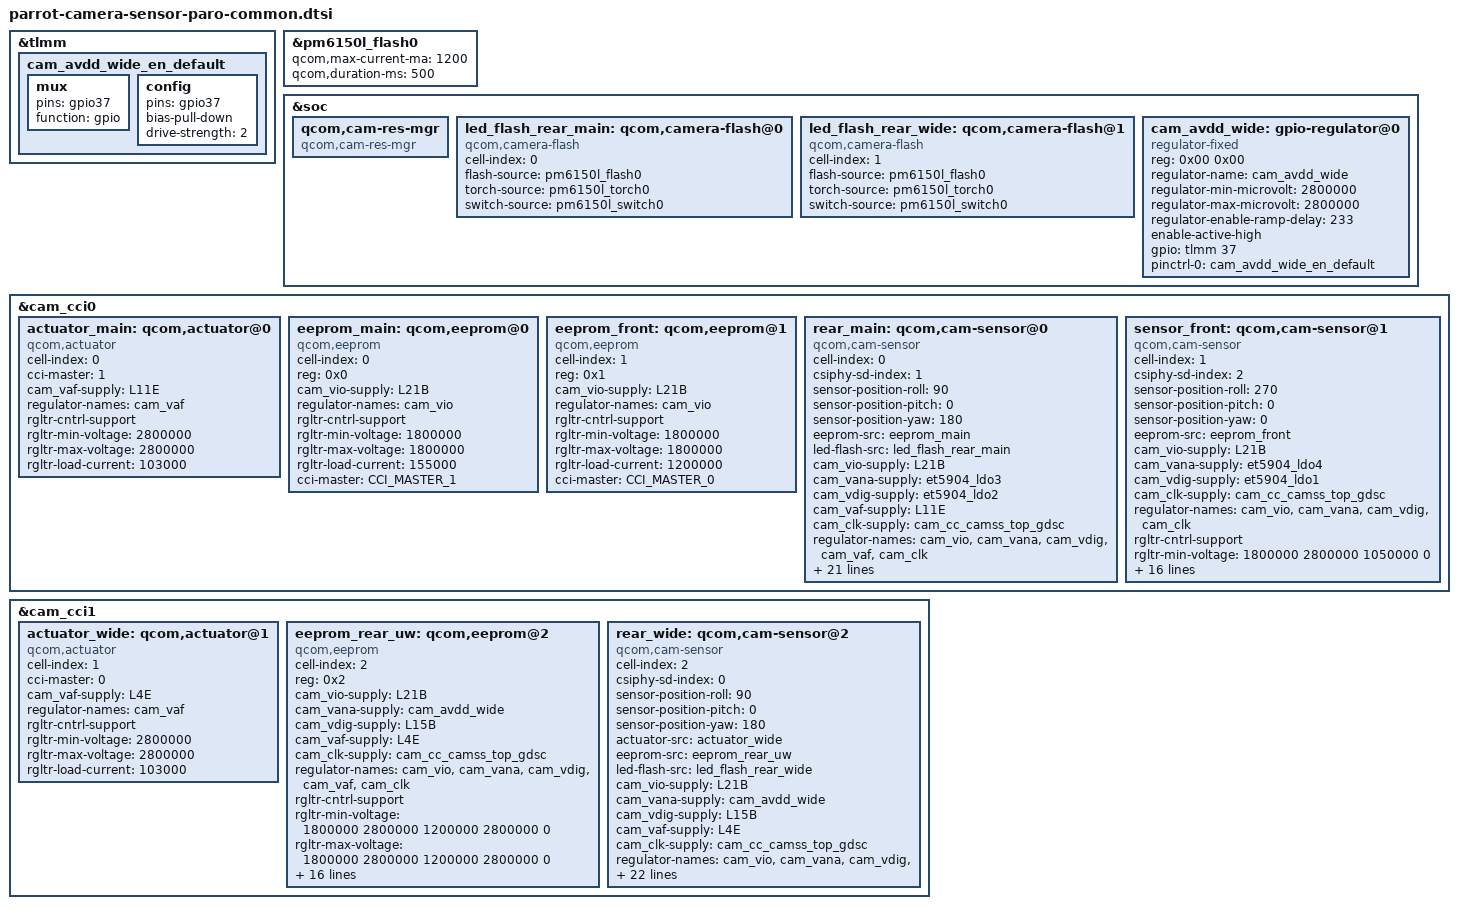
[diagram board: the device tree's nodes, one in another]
/*
   This base is original from "cape-camera-sensor-bronco-common.dtsi"
*/
#include <dt-bindings/clock/qcom,camcc-parrot.h>
#include <dt-bindings/msm-camera.h>

&tlmm {
	cam_avdd_wide_en_default: cam_avdd_wide_en_default {
		mux {
			pins = "gpio37";
			function = "gpio";
		};

		config {
			pins = "gpio37";
			bias-pull-down; /* PULL DOWN */
			drive-strength = <2>; /* 2 MA */
		};
	};

};

&pm6150l_flash0{
	qcom,max-current-ma = <1200>;
	qcom,duration-ms = <500>;
};

&soc {
	qcom,cam-res-mgr {
		compatible = "qcom,cam-res-mgr";
		status = "ok";
	};

	led_flash_rear_main: qcom,camera-flash@0 {
		cell-index = <0>;
		compatible = "qcom,camera-flash";
		flash-source = <&pm6150l_flash0>;
		torch-source = <&pm6150l_torch0>;
		switch-source = <&pm6150l_switch0>;
		status = "ok";
	};

	led_flash_rear_wide: qcom,camera-flash@1 {
		cell-index = <1>;
		compatible = "qcom,camera-flash";
		flash-source = <&pm6150l_flash0>;
		torch-source = <&pm6150l_torch0>;
		switch-source = <&pm6150l_switch0>;
		status = "ok";
	};

	cam_avdd_wide: gpio-regulator@0 {
		compatible = "regulator-fixed";
		reg = <0x00 0x00>;
		regulator-name = "cam_avdd_wide";
		regulator-min-microvolt = <2800000>;
		regulator-max-microvolt = <2800000>;
		regulator-enable-ramp-delay = <233>;
		enable-active-high;
		gpio = <&tlmm 37 0>;
		pinctrl-names = "default";
		pinctrl-0 = <&cam_avdd_wide_en_default>;
	};

};

&cam_cci0 {
	actuator_main: qcom,actuator@0 {
		cell-index = <0>;
		compatible = "qcom,actuator";
		cci-master = <1>;
		cam_vaf-supply = <&L11E>;
		regulator-names = "cam_vaf";
		rgltr-cntrl-support;
		rgltr-min-voltage = <2800000>;
		rgltr-max-voltage = <2800000>;
		rgltr-load-current = <103000>;
		status = "ok";
	};

	eeprom_main: qcom,eeprom@0 {
		cell-index = <0>;
		reg = <0x0>;
		compatible = "qcom,eeprom";
		cam_vio-supply  = <&L21B>;
		regulator-names = "cam_vio";
		rgltr-cntrl-support;
		rgltr-min-voltage  = <1800000>;
		rgltr-max-voltage  = <1800000>;
		rgltr-load-current = <155000>;
		cci-master = <CCI_MASTER_1>;
		status = "ok";
	};

	eeprom_front: qcom,eeprom@1 {
		cell-index = <1>;
		reg = <0x1>;
		compatible = "qcom,eeprom";
		cam_vio-supply  = <&L21B>;
		regulator-names = "cam_vio";
		rgltr-cntrl-support;
		rgltr-min-voltage  = <1800000>;
		rgltr-max-voltage  = <1800000>;
		rgltr-load-current = <1200000>;
		cci-master = <CCI_MASTER_0>;
		status = "ok";
	};

	rear_main: qcom,cam-sensor@0 {
		cell-index = <0>;
		compatible = "qcom,cam-sensor";
		csiphy-sd-index = <1>;
		sensor-position-roll = <90>;
		sensor-position-pitch = <0>;
		sensor-position-yaw = <180>;
		// actuator-src  = <&actuator_main>;
		eeprom-src    = <&eeprom_main>;
		led-flash-src = <&led_flash_rear_main>;
		cam_vio-supply  = <&L21B>;
		cam_vana-supply = <&et5904_ldo3>;
		cam_vdig-supply = <&et5904_ldo2>;
		cam_vaf-supply = <&L11E>;
		cam_clk-supply  = <&cam_cc_camss_top_gdsc>;
		regulator-names = "cam_vio", "cam_vana", "cam_vdig", "cam_vaf", "cam_clk" ;
		rgltr-cntrl-support;
		rgltr-min-voltage  = <1800000 2800000 1100000 2800000 0>;
		rgltr-max-voltage  = <1800000 2800000 1104000 2800000 0>;
		rgltr-load-current = <155000 155000 680000 103000 0>;
		gpio-no-mux = <0>;
		pinctrl-names = "cam_default", "cam_suspend";
		pinctrl-0 = <&cam_sensor_mclk1_active	&cam_sensor_active_rst1>;
		pinctrl-1 = <&cam_sensor_mclk1_suspend	&cam_sensor_suspend_rst1>;
		gpios = <&tlmm 40 0>, <&tlmm 45 0>;
		gpio-reset = <1>;
		gpio-req-tbl-num   = <0 1>;
		gpio-req-tbl-flags = <1 0>;
		gpio-req-tbl-label = "CAMIF_MCLK1", "CAM_RESET1";
		cci-master = <CCI_MASTER_1>;
		clocks = <&camcc CAM_CC_MCLK1_CLK>;
		clock-names = "cam_clk";
		clock-cntl-level = "nominal";
		clock-rates = <24000000>;
		status = "ok";
	};

	sensor_front: qcom,cam-sensor@1 {
		cell-index = <1>;
		compatible = "qcom,cam-sensor";
		csiphy-sd-index = <2>;
		sensor-position-roll = <270>;
		sensor-position-pitch = <0>;
		sensor-position-yaw = <0>;
		eeprom-src   = <&eeprom_front>;
		cam_vio-supply  = <&L21B>;
		cam_vana-supply = <&et5904_ldo4>;
		cam_vdig-supply = <&et5904_ldo1>;
		cam_clk-supply  = <&cam_cc_camss_top_gdsc>;
		regulator-names = "cam_vio", "cam_vana", "cam_vdig", "cam_clk";
		rgltr-cntrl-support;
		rgltr-min-voltage  = <1800000 2800000 1050000 0>;
		rgltr-max-voltage  = <1800000 2800000 1050000 0>;
		rgltr-load-current = <1200000 1200000 680000 0>;
		gpio-no-mux = <0>;
		pinctrl-names = "cam_default", "cam_suspend";
		pinctrl-0 = <&cam_sensor_mclk0_active	&cam_sensor_active_rst0>;
		pinctrl-1 = <&cam_sensor_mclk0_suspend	&cam_sensor_suspend_rst0>;
		gpios = <&tlmm 39 0>, <&tlmm 44 0>;
		gpio-reset = <1>;
		gpio-req-tbl-num = <0 1>;
		gpio-req-tbl-flags = <1 0>;
		gpio-req-tbl-label = "CAMIF_MCLK0", "CAM_RESET0";
		cci-master = <CCI_MASTER_0>;
		clocks = <&camcc CAM_CC_MCLK0_CLK>;
		clock-names = "cam_clk";
		clock-cntl-level = "nominal";
		clock-rates = <24000000>;
		status = "ok";
	};
};

&cam_cci1 {
	actuator_wide: qcom,actuator@1 {
		cell-index = <1>;
		compatible = "qcom,actuator";
		cci-master = <0>;
		cam_vaf-supply = <&L4E>;
		regulator-names = "cam_vaf";
		rgltr-cntrl-support;
		rgltr-min-voltage = <2800000>;
		rgltr-max-voltage = <2800000>;
		rgltr-load-current = <103000>;
		status = "ok";
	};

	eeprom_rear_uw: qcom,eeprom@2 {
		cell-index = <2>;
		reg = <0x2>;
		compatible = "qcom,eeprom";
		cam_vio-supply  = <&L21B>;
		cam_vana-supply = <&cam_avdd_wide>;
		cam_vdig-supply = <&L15B>;
		cam_vaf-supply = <&L4E>;
		cam_clk-supply  = <&cam_cc_camss_top_gdsc>;
		regulator-names = "cam_vio", "cam_vana", "cam_vdig", "cam_vaf", "cam_clk";
		rgltr-cntrl-support;
		rgltr-min-voltage  = <1800000 2800000 1200000 2800000 0>;
		rgltr-max-voltage  = <1800000 2800000 1200000 2800000 0>;
		rgltr-load-current = <1200000 1200000 680000 103000 0>;
		gpio-no-mux = <0>;
		pinctrl-names = "cam_default", "cam_suspend";
		pinctrl-0 = <&cam_sensor_mclk2_active	&cam_sensor_active_rst2>;
		pinctrl-1 = <&cam_sensor_mclk2_suspend	&cam_sensor_suspend_rst2>;
		gpios = <&tlmm 41 0>, <&tlmm 46 0>;
		gpio-reset = <1>;
		gpio-req-tbl-num   = <0 1>;
		gpio-req-tbl-flags = <1 0>;
		gpio-req-tbl-label = "CAMIF_MCLK2", "CAM_RESET2";
		cci-master = <CCI_MASTER_0>;
		clocks = <&camcc CAM_CC_MCLK2_CLK>;
		clock-names = "cam_clk";
		clock-cntl-level = "nominal";
		clock-rates = <24000000>;
		status = "ok";
	};

	rear_wide: qcom,cam-sensor@2 {
		cell-index = <2>;
		compatible = "qcom,cam-sensor";
		csiphy-sd-index = <0>;
		sensor-position-roll = <90>;
		sensor-position-pitch = <0>;
		sensor-position-yaw = <180>;
		actuator-src  = <&actuator_wide>;
		eeprom-src    = <&eeprom_rear_uw>;
		led-flash-src = <&led_flash_rear_wide>;
		cam_vio-supply  = <&L21B>;
		cam_vana-supply = <&cam_avdd_wide>;
		cam_vdig-supply = <&L15B>;
		cam_vaf-supply = <&L4E>;
		cam_clk-supply  = <&cam_cc_camss_top_gdsc>;
		regulator-names = "cam_vio", "cam_vana", "cam_vdig", "cam_vaf", "cam_clk";
		rgltr-cntrl-support;
		rgltr-min-voltage  = <1800000 2800000 1200000 2800000 0>;
		rgltr-max-voltage  = <1800000 2800000 1200000 2800000 0>;
		rgltr-load-current = <1200000 1200000 680000 103000 0>;
		gpio-no-mux = <0>;
		pinctrl-names = "cam_default", "cam_suspend";
		pinctrl-0 = <&cam_sensor_mclk2_active	&cam_sensor_active_rst2>;
		pinctrl-1 = <&cam_sensor_mclk2_suspend	&cam_sensor_suspend_rst2>;
		gpios = <&tlmm 41 0>, <&tlmm 46 0>;
		gpio-reset = <1>;
		gpio-req-tbl-num   = <0 1>;
		gpio-req-tbl-flags = <1 0>;
		gpio-req-tbl-label = "CAMIF_MCLK2", "CAM_RESET2";
		cci-master = <CCI_MASTER_0>;
		clocks = <&camcc CAM_CC_MCLK2_CLK>;
		clock-names = "cam_clk";
		clock-cntl-level = "nominal";
		clock-rates = <24000000>;
		status = "ok";
	};
};
